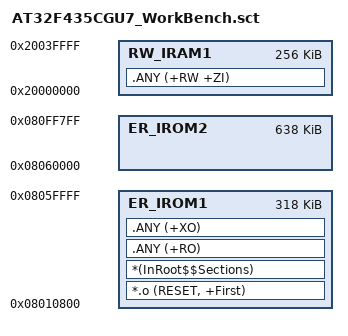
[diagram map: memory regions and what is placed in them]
; *************************************************************
; *** Scatter-Loading Description File generated by uVision ***
; *************************************************************

LR_IROM1 0x08010800 0x000EF800  {    ; load region size_region
  ER_IROM1 0x08010800 0x0004F800  {  ; load address = execution address
   *.o (RESET, +First)
   *(InRoot$$Sections)
   .ANY (+RO)
   .ANY (+XO)
  }
  ER_IROM2 0x08060000 0x9F800  
  {
	
  }
  RW_IRAM1 0x20000000 0x00040000  {  ; RW data
   .ANY (+RW +ZI)
  }
}

